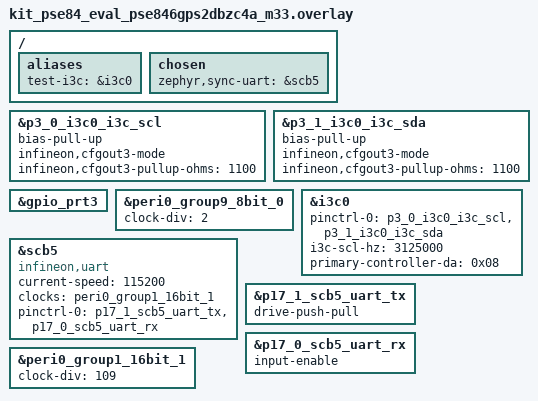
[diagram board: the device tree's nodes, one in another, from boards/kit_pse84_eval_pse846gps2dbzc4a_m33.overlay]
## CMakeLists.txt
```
# SPDX-FileCopyrightText: Copyright (c) 2026 Infineon Technologies AG,
# SPDX-FileCopyrightText: or an affiliate of Infineon Technologies AG. All rights reserved.
#
# SPDX-License-Identifier: Apache-2.0

cmake_minimum_required(VERSION 3.20.0)
find_package(Zephyr REQUIRED HINTS $ENV{ZEPHYR_BASE})
project(dual_board_loopback_controller)

file(GLOB app_sources CONFIGURE_DEPENDS src/*.c)
list(REMOVE_ITEM app_sources "${CMAKE_CURRENT_SOURCE_DIR}/src/test_harness.c")
target_sources(app PRIVATE ${app_sources})
target_sources_ifdef(CONFIG_I3C_DUAL_BOARD_LOOPBACK_META_TESTS app PRIVATE src/test_harness.c)

target_include_directories(app PRIVATE ${CMAKE_CURRENT_SOURCE_DIR}/../../common)
```

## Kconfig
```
# SPDX-FileCopyrightText: Copyright (c) 2026 Infineon Technologies AG,
# SPDX-FileCopyrightText: or an affiliate of Infineon Technologies AG. All rights reserved.
#
# SPDX-License-Identifier: Apache-2.0

mainmenu "I3C loopback test (controller)"

source "Kconfig.zephyr"

menu "I3C loopback bench options"

config I3C_DUAL_BOARD_LOOPBACK_META_TESTS
	bool "Build the meta tests that exercise the loopback fixture"
	help
	  Build the ``meta_*`` ZTESTs in test_harness.c.  These test the
	  fixture in main.c rather than the I3C driver: they deliberately
	  corrupt the target descriptor to prove the recovery path in
	  dual_board_loopback_heal_target() puts it back.  Because they run before
	  the driver tests and mutate shared bus state, a regression in the
	  fixture makes them cascade into every later test, so keep them off
	  for routine runs and enable them when changing the harness.

endmenu
```

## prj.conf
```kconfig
# SPDX-FileCopyrightText: Copyright (c) 2026 Infineon Technologies AG,
# SPDX-FileCopyrightText: or an affiliate of Infineon Technologies AG. All rights reserved.
#
# SPDX-License-Identifier: Apache-2.0
#
# Controller app for the dual_board_loopback two-board test pair.

CONFIG_ZTEST=y
CONFIG_ZTEST_STACK_SIZE=4096

CONFIG_PRINTK_SYNC=y
CONFIG_FAULT_DUMP=2
CONFIG_LOG=y
CONFIG_SERIAL=y

# I3C: controller-only build for max coverage of the controller paths
CONFIG_I3C=y
CONFIG_I3C_CONTROLLER_ROLE_ONLY=y
CONFIG_I3C_USE_IBI=y

# Misc
CONFIG_PINCTRL_KEEP_SLEEP_STATE=y
CONFIG_MAIN_STACK_SIZE=4096
CONFIG_CLOCK_CONTROL=y

# For light testing of PM APIs - this suite does not do extensive PM
# validaton
CONFIG_PM_DEVICE=y
```

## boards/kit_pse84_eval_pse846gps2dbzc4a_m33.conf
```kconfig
# SPDX-FileCopyrightText: Copyright (c) 2026 Infineon Technologies AG,
# SPDX-FileCopyrightText: or an affiliate of Infineon Technologies AG. All rights reserved.
#
# SPDX-License-Identifier: Apache-2.0
#
# Bench configuration for KIT_PSE84_EVAL (PSE846GPS2DBZC4A, M33 core).
#
# The SOM has a BMM350 magnetometer wired to the same I3C0 pads the test
# controller drives, with no power-enable or isolation jumper exposed.
# It only joins ENTDAA while it is in I3C mode: it falls back to its I2C
# interface whenever anything issues a soft reset to it, and only a power
# cycle puts it back.  Because the suite cannot rely on it being there
# from one run to the next, the placeholder descriptor is left disabled
# and the address it would take is treated as free.
#
# Re-enable these if the BMM350 is made to stay in I3C mode.  The PID was
# captured live from DEV_CHAR_TABLE on this SOM.
# CONFIG_I3C_DUAL_BOARD_LOOPBACK_BENCH_HAS_PERMANENT_TARGET=y
# CONFIG_I3C_DUAL_BOARD_LOOPBACK_BENCH_PERMANENT_TARGET_PID_HI=0x0770
# CONFIG_I3C_DUAL_BOARD_LOOPBACK_BENCH_PERMANENT_TARGET_PID_LO=0x10331000
# CONFIG_I3C_DUAL_BOARD_LOOPBACK_BENCH_PERMANENT_TARGET_INIT_DA=0x15
```

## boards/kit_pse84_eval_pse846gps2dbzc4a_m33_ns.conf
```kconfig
# SPDX-FileCopyrightText: Copyright (c) 2026 Infineon Technologies AG,
# SPDX-FileCopyrightText: or an affiliate of Infineon Technologies AG. All rights reserved.
#
# SPDX-License-Identifier: Apache-2.0
#
# Bench configuration for KIT_PSE84_EVAL (PSE846GPS2DBZC4A, M33 non-secure
# core, TF-M).
#
# The SOM has a BMM350 magnetometer wired to the same I3C0 pads the test
# controller drives, with no power-enable or isolation jumper exposed.
# It only joins ENTDAA while it is in I3C mode: it falls back to its I2C
# interface whenever anything issues a soft reset to it, and only a power
# cycle puts it back.  Because the suite cannot rely on it being there
# from one run to the next, the placeholder descriptor is left disabled
# and the address it would take is treated as free.
#
# Re-enable these if the BMM350 is made to stay in I3C mode.  The PID was
# captured live from DEV_CHAR_TABLE on this SOM.
# CONFIG_I3C_DUAL_BOARD_LOOPBACK_BENCH_HAS_PERMANENT_TARGET=y
# CONFIG_I3C_DUAL_BOARD_LOOPBACK_BENCH_PERMANENT_TARGET_PID_HI=0x0770
# CONFIG_I3C_DUAL_BOARD_LOOPBACK_BENCH_PERMANENT_TARGET_PID_LO=0x10331000
# CONFIG_I3C_DUAL_BOARD_LOOPBACK_BENCH_PERMANENT_TARGET_INIT_DA=0x15
```

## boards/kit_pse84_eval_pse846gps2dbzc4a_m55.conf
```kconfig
# SPDX-FileCopyrightText: Copyright (c) 2026 Infineon Technologies AG,
# SPDX-FileCopyrightText: or an affiliate of Infineon Technologies AG. All rights reserved.
#
# SPDX-License-Identifier: Apache-2.0
#
# Bench configuration for KIT_PSE84_EVAL (PSE846GPS2DBZC4A, M55 core).
#
# This core must be built with --sysbuild: the CM55 image only boots once
# the CM33 enable_cm55 companion has released it, and sysbuild is what
# generates that companion.  A command-line Kconfig override has to name
# the image as well, because a bare -DCONFIG_* lands in sysbuild's own
# namespace and never reaches the application:
#
#   west build -b kit_pse84_eval/pse846gps2dbzc4a/m55 --sysbuild \
#         tests/drivers/i3c/dual_board_loopback/controller_driven/i3c_controller \
#         -- -Di3c_controller_CONFIG_I3C_USE_IBI=n
#
# The SOM has a BMM350 magnetometer wired to the same I3C0 pads the test
# controller drives, with no power-enable or isolation jumper exposed.
# It only joins ENTDAA while it is in I3C mode: it falls back to its I2C
# interface whenever anything issues a soft reset to it, and only a power
# cycle puts it back.  Because the suite cannot rely on it being there
# from one run to the next, the placeholder descriptor is left disabled
# and the address it would take is treated as free.
#
# Re-enable these if the BMM350 is made to stay in I3C mode.  The PID was
# captured live from DEV_CHAR_TABLE on this SOM.
# CONFIG_I3C_DUAL_BOARD_LOOPBACK_BENCH_HAS_PERMANENT_TARGET=y
# CONFIG_I3C_DUAL_BOARD_LOOPBACK_BENCH_PERMANENT_TARGET_PID_HI=0x0770
# CONFIG_I3C_DUAL_BOARD_LOOPBACK_BENCH_PERMANENT_TARGET_PID_LO=0x10331000
# CONFIG_I3C_DUAL_BOARD_LOOPBACK_BENCH_PERMANENT_TARGET_INIT_DA=0x15
```

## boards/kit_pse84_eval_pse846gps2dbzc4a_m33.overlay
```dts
/*
 * SPDX-FileCopyrightText: Copyright (c) 2026 Infineon Technologies AG,
 * SPDX-FileCopyrightText: or an affiliate of Infineon Technologies AG. All rights reserved.
 *
 * SPDX-License-Identifier: Apache-2.0
 *
 * Board overlay for the dual_board_loopback CONTROLLER (Board A) on
 * KIT_PSE84_EVAL (M33 core).
 *
 * Topology — I3C bus between two boards:
 *
 *   A.I3C0_SCL  ── B.I3C0_SCL    (P3.0 / B.P3.0)
 *   A.I3C0_SDA  ── B.I3C0_SDA    (P3.1 / B.P3.1)
 *
 * UART sync channel (separate from the I3C bus):
 *
 *   A.SCB5_TX (P17.1)  ──── B.SCB5_RX (P17.0)
 *   A.SCB5_RX (P17.0)  ──── B.SCB5_TX (P17.1)
 *
 * SCB5 was selected after SCB1 (separate non-LPSS IP block at
 * 0x42d00000) refused to drain its TX FIFO regardless of clock /
 * pinctrl configuration.  SCB5 (LPSS, 0x429d0000) is the same UART
 * instance used by tests/drivers/uart/uart_async_api on this board
 * and was validated end-to-end by tests/drivers/serial/uart_sync_loopback.
 */

/ {
	aliases {
		test-i3c = &i3c0;
	};

	chosen {
		zephyr,sync-uart = &scb5;
	};
};

/*
 * Mandatory CFGOUT3 mode on the I3C SCL/SDA pads.  Without this the DW
 * I3C ACK detector cannot sample SDA and every transfer reports
 * ADDRESS_NACK (see tests/drivers/i3c/i3c_i2c/boards/<...>.overlay for
 * the full rationale).
 */
&p3_0_i3c0_i3c_scl {
	bias-pull-up;
	infineon,cfgout3-mode;
	infineon,cfgout3-pullup-ohms = <1100>;
};

&p3_1_i3c0_i3c_sda {
	bias-pull-up;
	infineon,cfgout3-mode;
	infineon,cfgout3-pullup-ohms = <1100>;
};

&gpio_prt3 {
	status = "okay";
};

/*
 * I3C protocol clock (CORE_CLK).
 *
 * CLK_HF[13] = CLKPATH0 / 4 = 400 MHz / 4 = 100 MHz.
 * peri0_group9_8bit_0 divides that further: 100 MHz / 2 = 50 MHz.
 *
 * The core clock must exceed 5 * i3c-scl-hz: the driver computes the
 * push-pull lcnt as DIV_ROUND_UP(core, scl) - hcnt with hcnt floored at
 * 5, so a slower core underflows and clamps lcnt to 255, collapsing SCL
 * to core/260 instead of the requested rate.  At 50 MHz, hcnt=5 lcnt=11
 * gives the requested 3.125 MHz.
 */
&peri0_group9_8bit_0 {
	clock-div = <2>;
	status = "okay";
};

&i3c0 {
	pinctrl-0 = <&p3_0_i3c0_i3c_scl &p3_1_i3c0_i3c_sda>;
	pinctrl-names = "default";
	i3c-scl-hz = <3125000>;
	primary-controller-da = <0x08>;
	status = "okay";

	/*
	 * Note: Board B is intentionally NOT declared as an i3c child
	 * node in DT.  Doing so would require a real driver matching the
	 * compatible (DEVICE_DT_GET would otherwise link-fail).  The
	 * controller-side test code instead populates a static
	 * `struct i3c_device_desc` programmatically and calls
	 * i3c_attach_i3c_device() at suite setup, which exercises the
	 * dynamic-attach path of the driver.
	 */
};

/*
 * SCB5 — UART sync channel between Board A and Board B.
 *   P17.1 SCB5_UART_TX, P17.0 SCB5_UART_RX
 * Pinctrl reused from the SoC pin database (omit-if-no-ref).
 * (See file header for SCB1 history.)
 */
scb5_sync_uart: &scb5 {
	compatible = "infineon,uart";
	current-speed = <115200>;
	clocks = <&peri0_group1_16bit_1>;
	pinctrl-0 = <&p17_1_scb5_uart_tx &p17_0_scb5_uart_rx>;
	pinctrl-names = "default";
	status = "okay";
};

&p17_1_scb5_uart_tx {
	drive-push-pull;
};

&p17_0_scb5_uart_rx {
	input-enable;
};

&peri0_group1_16bit_1 {
	clock-div = <109>;
	status = "okay";
};
```

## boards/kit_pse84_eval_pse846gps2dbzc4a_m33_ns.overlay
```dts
/*
 * SPDX-FileCopyrightText: Copyright (c) 2026 Infineon Technologies AG,
 * SPDX-FileCopyrightText: or an affiliate of Infineon Technologies AG. All rights reserved.
 *
 * SPDX-License-Identifier: Apache-2.0
 *
 * Board overlay for the dual_board_loopback CONTROLLER (Board A) on
 * KIT_PSE84_EVAL (M33 non-secure core, TF-M).
 *
 * Topology — I3C bus between two boards:
 *
 *   A.I3C0_SCL  ── B.I3C0_SCL    (P3.0 / B.P3.0)
 *   A.I3C0_SDA  ── B.I3C0_SDA    (P3.1 / B.P3.1)
 *
 * UART sync channel (separate from the I3C bus):
 *
 *   A.SCB5_TX (P17.1)  ──── B.SCB5_RX (P17.0)
 *   A.SCB5_RX (P17.0)  ──── B.SCB5_TX (P17.1)
 */

/ {
	aliases {
		test-i3c = &i3c0;
	};

	chosen {
		zephyr,sync-uart = &scb5;
	};
};

/*
 * Mandatory CFGOUT3 mode on the I3C SCL/SDA pads.  Without this the DW
 * I3C ACK detector cannot sample SDA and every transfer reports
 * ADDRESS_NACK (see tests/drivers/i3c/i3c_i2c/boards/<...>.overlay for
 * the full rationale).
 */
&p3_0_i3c0_i3c_scl {
	bias-pull-up;
	infineon,cfgout3-mode;
	infineon,cfgout3-pullup-ohms = <1100>;
};

&p3_1_i3c0_i3c_sda {
	bias-pull-up;
	infineon,cfgout3-mode;
	infineon,cfgout3-pullup-ohms = <1100>;
};

&gpio_prt3 {
	status = "okay";
};

/*
 * I3C protocol clock (CORE_CLK).
 *
 * CLK_HF[13] = CLKPATH0 / 4 = 400 MHz / 4 = 100 MHz.
 * peri0_group9_8bit_0 divides that further: 100 MHz / 2 = 50 MHz.
 *
 * The core clock must exceed 5 * i3c-scl-hz: the driver computes the
 * push-pull lcnt as DIV_ROUND_UP(core, scl) - hcnt with hcnt floored at
 * 5, so a slower core underflows and clamps lcnt to 255, collapsing SCL
 * to core/260 instead of the requested rate.  At 50 MHz, hcnt=5 lcnt=11
 * gives the requested 3.125 MHz.
 */
&peri0_group9_8bit_0 {
	clock-div = <2>;
	status = "okay";
};

&i3c0 {
	pinctrl-0 = <&p3_0_i3c0_i3c_scl &p3_1_i3c0_i3c_sda>;
	pinctrl-names = "default";
	i3c-scl-hz = <3125000>;
	primary-controller-da = <0x08>;
	status = "okay";

	/*
	 * Note: Board B is intentionally NOT declared as an i3c child
	 * node in DT.  Doing so would require a real driver matching the
	 * compatible (DEVICE_DT_GET would otherwise link-fail).  The
	 * controller-side test code instead populates a static
	 * `struct i3c_device_desc` programmatically and calls
	 * i3c_attach_i3c_device() at suite setup, which exercises the
	 * dynamic-attach path of the driver.
	 */
};

/*
 * SCB5 — UART sync channel between Board A and Board B.
 *   P17.1 SCB5_UART_TX, P17.0 SCB5_UART_RX
 * Pinctrl reused from the SoC pin database (omit-if-no-ref).
 */
scb5_sync_uart: &scb5 {
	compatible = "infineon,uart";
	current-speed = <115200>;
	clocks = <&peri0_group1_16bit_1>;
	pinctrl-0 = <&p17_1_scb5_uart_tx &p17_0_scb5_uart_rx>;
	pinctrl-names = "default";
	status = "okay";
};

&p17_1_scb5_uart_tx {
	drive-push-pull;
};

&p17_0_scb5_uart_rx {
	input-enable;
};

&peri0_group1_16bit_1 {
	clock-div = <109>;
	status = "okay";
};
```

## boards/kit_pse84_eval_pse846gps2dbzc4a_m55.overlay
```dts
/*
 * SPDX-FileCopyrightText: Copyright (c) 2026 Infineon Technologies AG,
 * SPDX-FileCopyrightText: or an affiliate of Infineon Technologies AG. All rights reserved.
 *
 * SPDX-License-Identifier: Apache-2.0
 *
 * Board overlay for the dual_board_loopback CONTROLLER (Board A) on
 * KIT_PSE84_EVAL (M55 core).
 *
 * Topology — I3C bus between two boards:
 *
 *   A.I3C0_SCL  ── B.I3C0_SCL    (P3.0 / B.P3.0)
 *   A.I3C0_SDA  ── B.I3C0_SDA    (P3.1 / B.P3.1)
 *
 * UART sync channel (separate from the I3C bus):
 *
 *   A.SCB5_TX (P17.1)  ──── B.SCB5_RX (P17.0)
 *   A.SCB5_RX (P17.0)  ──── B.SCB5_TX (P17.1)
 *
 * SCB5 was selected after SCB1 (separate non-LPSS IP block at
 * 0x42d00000) refused to drain its TX FIFO regardless of clock /
 * pinctrl configuration.  SCB5 (LPSS, 0x429d0000) is the same UART
 * instance used by tests/drivers/uart/uart_async_api on this board
 * and was validated end-to-end by tests/drivers/serial/uart_sync_loopback.
 */

/ {
	aliases {
		test-i3c = &i3c0;
	};

	chosen {
		zephyr,sync-uart = &scb5;
	};
};

/*
 * Mandatory CFGOUT3 mode on the I3C SCL/SDA pads.  Without this the DW
 * I3C ACK detector cannot sample SDA and every transfer reports
 * ADDRESS_NACK (see tests/drivers/i3c/i3c_i2c/boards/<...>.overlay for
 * the full rationale).
 */
&p3_0_i3c0_i3c_scl {
	bias-pull-up;
	infineon,cfgout3-mode;
	infineon,cfgout3-pullup-ohms = <1100>;
};

&p3_1_i3c0_i3c_sda {
	bias-pull-up;
	infineon,cfgout3-mode;
	infineon,cfgout3-pullup-ohms = <1100>;
};

&gpio_prt3 {
	status = "okay";
};

/*
 * I3C protocol clock (CORE_CLK).
 *
 * CLK_HF[13] = CLKPATH0 / 4 = 400 MHz / 4 = 100 MHz.
 * peri0_group9_8bit_0 divides that further: 100 MHz / 2 = 50 MHz.
 *
 * The core clock must exceed 5 * i3c-scl-hz: the driver computes the
 * push-pull lcnt as DIV_ROUND_UP(core, scl) - hcnt with hcnt floored at
 * 5, so a slower core underflows and clamps lcnt to 255, collapsing SCL
 * to core/260 instead of the requested rate.  At 50 MHz, hcnt=5 lcnt=11
 * gives the requested 3.125 MHz.
 */
&peri0_group9_8bit_0 {
	clock-div = <2>;
	status = "okay";
};

&i3c0 {
	pinctrl-0 = <&p3_0_i3c0_i3c_scl &p3_1_i3c0_i3c_sda>;
	pinctrl-names = "default";
	i3c-scl-hz = <3125000>;
	primary-controller-da = <0x08>;
	status = "okay";

	/*
	 * Note: Board B is intentionally NOT declared as an i3c child
	 * node in DT.  Doing so would require a real driver matching the
	 * compatible (DEVICE_DT_GET would otherwise link-fail).  The
	 * controller-side test code instead populates a static
	 * `struct i3c_device_desc` programmatically and calls
	 * i3c_attach_i3c_device() at suite setup, which exercises the
	 * dynamic-attach path of the driver.
	 */
};

/*
 * SCB5 — UART sync channel between Board A and Board B.
 *   P17.1 SCB5_UART_TX, P17.0 SCB5_UART_RX
 * Pinctrl reused from the SoC pin database (omit-if-no-ref).
 * (See file header for SCB1 history.)
 */
scb5_sync_uart: &scb5 {
	compatible = "infineon,uart";
	current-speed = <115200>;
	clocks = <&peri0_group1_16bit_1>;
	pinctrl-0 = <&p17_1_scb5_uart_tx &p17_0_scb5_uart_rx>;
	pinctrl-names = "default";
	status = "okay";
};

&p17_1_scb5_uart_tx {
	drive-push-pull;
};

&p17_0_scb5_uart_rx {
	input-enable;
};

&peri0_group1_16bit_1 {
	clock-div = <109>;
	status = "okay";
};
```

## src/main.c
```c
/*
 * SPDX-FileCopyrightText: Copyright (c) 2026 Infineon Technologies AG,
 * SPDX-FileCopyrightText: or an affiliate of Infineon Technologies AG. All rights reserved.
 *
 * SPDX-License-Identifier: Apache-2.0
 *
 * Controller-side fixture for the dual_board_loopback two-board test pair.
 * Owns DT handles, the Board B target descriptor (attached at suite
 * setup), and the ZTEST_SUITE registration.  Per-test ZTEST() bodies
 * live in the other src/test_*.c files.
 */

#include "test_common.h"
#include "test_identity.h"

#include <zephyr/devicetree.h>
#include <zephyr/sys/sys_io.h>
#include <zephyr/drivers/i3c.h>
#include <zephyr/drivers/i3c/ccc.h>
#include <zephyr/drivers/uart.h>
#include <zephyr/kernel.h>
#include <zephyr/logging/log.h>
#include <zephyr/ztest.h>
#include <zephyr/init.h>
#include <string.h>

LOG_MODULE_REGISTER(dual_board_loopback_ctrl, LOG_LEVEL_INF);

/* Early boot marker to prove flash is working */
static int early_boot_marker(void)
{
	printk("\n\n*** CONTROLLER BUILD " __DATE__ " " __TIME__ " ***\n\n");
	return 0;
}
SYS_INIT(early_boot_marker, APPLICATION, 0);

/*
 * --------------------------------------------------------------------------
 * DT handles
 * --------------------------------------------------------------------------
 */
const struct device *const i3c_dev = DEVICE_DT_GET(DT_ALIAS(test_i3c));
const struct device *const sync_uart = DEVICE_DT_GET(DT_CHOSEN(zephyr_sync_uart));

/*
 * Stand-in driver instance for every peer descriptor this suite builds by
 * hand; see the comment on the declaration in test_common.h.
 */
const struct device i3c_peer_dev = {
	.name = "i3c-peer",
};

/*
 * Board B (I3C target) descriptor.  Both endpoints are known at build
 * time, so Board B is enumerated via SETDASA from its known static
 * address; PID is still carried so directed CCCs can verify identity.
 */
struct i3c_device_desc target_b_desc = {
	.bus = DEVICE_DT_GET(DT_ALIAS(test_i3c)),
	.dev = &i3c_peer_dev,
	.pid = TARGET_PID,
	.static_addr = TARGET_STATIC_ADDR,
	.init_dynamic_addr = TARGET_STATIC_ADDR,
	.flags = 0,
};

int dual_board_loopback_heal_target(void)
{
	struct i3c_ccc_address da = {.addr = CCC_ADDR_PAYLOAD(TARGET_STATIC_ADDR)};
	uint8_t prev_da = target_b_desc.dynamic_addr;
	int rc;

	if (prev_da == 0U) {
		prev_da = TARGET_STATIC_ADDR;
	}

	sync_send(sync_uart, "SOFT_RST");
	(void)sync_expect(sync_uart, "READY", K_MSEC(2000));
	(void)i3c_recover_bus(i3c_dev);
	k_msleep(200);
	(void)i3c_ccc_do_rstdaa_all(i3c_dev);

	/*
	 * SETDASA is only legal for a device with no dynamic address, and the
	 * driver keys the DAT entry on whatever address the descriptor holds
	 * at attach time. Detach, clear, re-attach so the CCC and the table
	 * agree the target is currently unaddressed. Detach frees the address
	 * slot named by the descriptor, so point it at the reserved address
	 * first; a stale DA would free the wrong slot and leak the real one.
	 */
	target_b_desc.dynamic_addr = TARGET_STATIC_ADDR;
	(void)i3c_detach_i3c_device(&target_b_desc);
	target_b_desc.dynamic_addr = 0U;

	rc = i3c_attach_i3c_device(&target_b_desc);
	if ((rc != 0) && (rc != -EALREADY)) {
		printk("[heal] re-attach failed (%d)\n", rc);
		target_b_desc.dynamic_addr = prev_da;
		return rc;
	}

	/* SETDASA (not ENTDAA) restores the known static address; ENTDAA
	 * could yield a different DA after arbitration against another
	 * on-bus target.
	 */
	rc = i3c_ccc_do_setdasa(&target_b_desc, da);
	if (rc != 0) {
		/* Restore prev_da so the next before_each retries instead of
		 * treating the target as permanently absent.
		 */
		target_b_desc.dynamic_addr = prev_da;
		return rc;
	}

	/*
	 * Re-attach rather than reattach: the driver only writes the DAT
	 * dynamic-address field when dynamic_addr is already set, and
	 * i3c_reattach_i3c_device() bails with -EADDRNOTAVAIL here because
	 * the attach above already claimed this address slot.
	 */
	(void)i3c_detach_i3c_device(&target_b_desc);
	target_b_desc.dynamic_addr = TARGET_STATIC_ADDR;
	rc = i3c_attach_i3c_device(&target_b_desc);
	if (rc == -EALREADY) {
		rc = 0;
	}

	return rc;
}

/* Suite setup: ready DT devices, handshake with Board B, attach and
 * enumerate it.
 */
static void *suite_setup(void)
{
	int rc;
	uint32_t t0, t1;

	printk(">>> SUITE_SETUP ENTER\n");

	t0 = (uint32_t)k_uptime_get();
	printk("[t=%u] device_is_ready checks\n", t0);
	zassert_true(device_is_ready(i3c_dev), "I3C controller %s not ready", i3c_dev->name);
	zassert_true(device_is_ready(sync_uart), "Sync UART %s not ready", sync_uart->name);

	/*
	 * Three-way HELLO with Board B over the sync UART; if it fails,
	 * skip i3c_bus_init() and let bus-traffic tests FAIL via
	 * I3C_DUAL_BOARD_LOOPBACK_REQUIRE_TARGET_DA() rather than crash the suite
	 * on the DW driver's NULL-deref CCC abort path.
	 */
	t1 = (uint32_t)k_uptime_get();
	printk("[t=%u] sync_handshake start\n", t1);
	/* Drain RX junk accumulated while Board B was being flashed. */
	sync_drain(sync_uart);
	{
		const k_timepoint_t deadline = sys_timepoint_calc(K_SECONDS(60));

		rc = -EAGAIN;
		while (!sys_timepoint_expired(deadline)) {
			char boot_line[SYNC_LINE_MAX];

			/*
			 * Board B announces BOOT until it is spoken to, so
			 * waiting for an announcement rather than assuming a
			 * listening peer is what makes the flashing order
			 * irrelevant: a Board B that is already running stopped
			 * announcing long ago, and a stale image answers HELLO
			 * just as readily as a freshly programmed one.
			 */
			if (sync_expect_line(sync_uart, "BOOT", boot_line, sizeof(boot_line),
					     sys_timepoint_timeout(deadline)) != 0) {
				break;
			}
			/* Answering stops the announcements. */
			if (sync_handshake(sync_uart, K_SECONDS(5)) != 0) {
				continue;
			}
			/* Programming Board B resets it twice on sysbuild
			 * targets, so a further announcement means the peer we
			 * just greeted is already gone.
			 */
			if (sync_expect_line(sync_uart, "BOOT", boot_line, sizeof(boot_line),
					     K_SECONDS(2)) != 0) {
				rc = 0;
				break;
			}
		}
	}
	t1 = (uint32_t)k_uptime_get();
	printk("[t=%u] sync_handshake => %d\n", t1, rc);
	if (rc != 0) {
		printk("*** TARGET ABSENT (sync_handshake rc=%d) — "
		       "skipping i3c_bus_init; bus-traffic tests will FAIL "
		       "via I3C_DUAL_BOARD_LOOPBACK_REQUIRE_TARGET_DA ***\n",
		       rc);
		return NULL;
	}

	/*
	 * Attach target_b BEFORE bus init so the driver's PID lookup
	 * matches it during ENTDAA and fills in dynamic_addr / bcr / dcr
	 * directly on our descriptor.
	 */
	t1 = (uint32_t)k_uptime_get();
	printk("[t=%u] attach target_b (PID 0x%04x%08x)\n", t1, (uint16_t)(TARGET_PID >> 32),
	       (uint32_t)(TARGET_PID & 0xFFFFFFFFU));
	rc = i3c_attach_i3c_device(&target_b_desc);
	zassert_ok(rc, "i3c_attach_i3c_device(target_b) failed (%d)", rc);

	t1 = (uint32_t)k_uptime_get();
	printk("[t=%u] calling i3c_bus_init\n", t1);
	{
		struct i3c_dev_list dev_list = {
			.i3c = &target_b_desc,
			.i2c = NULL,
			.num_i3c = 1,
			.num_i2c = 0,
		};

		rc = i3c_bus_init(i3c_dev, &dev_list);
	}
	t1 = (uint32_t)k_uptime_get();
	printk("[t=%u] i3c_bus_init => %d\n", t1, rc);
	printk("[t=%u] target_b dynamic_addr = 0x%02x  bcr=0x%02x  dcr=0x%02x\n",
	       (uint32_t)k_uptime_get(), target_b_desc.dynamic_addr, target_b_desc.bcr,
	       target_b_desc.dcr);

	if (target_b_desc.dynamic_addr == 0) {
		int hrc = dual_board_loopback_heal_target();

		printk("[setup] bus init left no DA; heal rc=%d DA=0x%02x\n", hrc,
		       target_b_desc.dynamic_addr);
	}

	if (target_b_desc.dynamic_addr == 0) {
		printk("*** TARGET NOT FOUND ON BUS — tests will skip ***\n");
	}

	/*
	 * The bench-permanent target descriptor (if any) stays attached
	 * for the whole suite: mid-suite RSTDAA broadcasts force every
	 * on-bus target to re-arbitrate, and without a bound descriptor
	 * the driver hands the next-free DA to the unknown PID and can
	 * end up stealing target_b's slot.
	 */

	return NULL;
}

static void suite_before_each(void *fixture)
{
	ARG_UNUSED(fixture);

	sync_drain(sync_uart);
	sync_send(sync_uart, "RESET");
	{
		char ready_line[128];
		int rc = sync_expect_line(sync_uart, "READY", ready_line, sizeof(ready_line),
					  K_MSEC(100));
		if (rc == 0) {
			LOG_INF("[before_each] %s", ready_line);
		}
	}

	/* If a previous test left target_b without a DA, recover via
	 * ENTDAA.  The bench-permanent descriptor (if any) remains
	 * attached so it doesn't steal target_b's slot.
	 */
	if (target_b_desc.dynamic_addr == 0U) {
		int rc = i3c_do_daa(i3c_dev);

		if (rc != 0) {
			printk("[before_each] ENTDAA recovery failed: %d\n", rc);
		}

		/* ENTDAA cannot match a descriptor the driver has detached,
		 * so fall back to re-attach + SETDASA.
		 */
		if (target_b_desc.dynamic_addr == 0U) {
			rc = dual_board_loopback_heal_target();
			printk("[before_each] SETDASA heal rc=%d DA=0x%02x\n", rc,
			       target_b_desc.dynamic_addr);
		}
	}

	/* Recover from any HALT state left by a previous test. */
	(void)i3c_recover_bus(i3c_dev);

	/* Probe target with a 1-byte write; retry on NACK (legitimate
	 * I3C flow control while the target clears SLAVE_BUSY).  Only
	 * re-enumerate if all retries fail.
	 */
	if (target_b_desc.dynamic_addr != 0U) {
		uint8_t probe = 0x00;
		struct i3c_msg msg = {
			.buf = &probe,
			.len = 1,
			.flags = I3C_MSG_WRITE | I3C_MSG_STOP,
		};
		int rc = -1;

		/* Probe the target: 20 × 10 ms (~200 ms total).  Memory
		 * notes: the target IP recovers from its post-large-W NACK
		 * state within ~100-200 ms.  k_msleep yields so kernel
		 * timers/IRQs can run.
		 */
		for (int attempt = 0; attempt < 20; attempt++) {
			rc = i3c_transfer(&target_b_desc, &msg, 1);
			if (rc == 0) {
				break;
			}
			k_msleep(10);
		}

		if (rc != 0) {
			printk("[before_each] probe failed (%d) after retries, "
			       "re-enumerating\n",
			       rc);

			rc = dual_board_loopback_heal_target();
			printk("[before_each] re-enum done, DA=0x%02x "
			       "rc=%d\n",
			       target_b_desc.dynamic_addr, rc);

			/* Post re-enum settle + verify, same 200 ms budget. */
			k_msleep(50);
			for (int attempt = 0; attempt < 20; attempt++) {
				rc = i3c_transfer(&target_b_desc, &msg, 1);
				if (rc == 0) {
					break;
				}
				k_msleep(10);
			}
			if (rc != 0) {
				printk("[before_each] post-renum probe still "
				       "failing (%d), keeping DA so subsequent "
				       "tests can retry recovery (this test "
				       "will fail rather than skip)\n",
				       rc);
				/*
				 * Do NOT clear target_b_desc.dynamic_addr.
				 * The target typically recovers within 100-200
				 * ms, so the next before_each's probe usually
				 * succeeds.  Clearing the DA marks the target
				 * dead and would skip the rest of the suite.
				 * Better policy: this test FAILs honestly,
				 * the next test gets a fresh recovery attempt.
				 */
			}
		}

		/* Clear sticky OVERFLOW/UNDERFLOW/PROTOCOL_ERR via directed
		 * GETSTATUS (databook §3.5.2 / §6.1.24: the controller NACKs
		 * further private xfers until GETSTATUS reads device status).
		 * If GETSTATUS itself NACKs, the IP halts — recover so the
		 * halt does not cascade.
		 */
		if (target_b_desc.dynamic_addr != 0U) {
			union i3c_ccc_getstatus gs;
			int gs_rc = i3c_ccc_do_getstatus_fmt1(&target_b_desc, &gs);

			if (gs_rc != 0) {
				LOG_WRN("[before_each] GETSTATUS failed: %d", gs_rc);
			} else if (gs.fmt1.status != 0U) {
				LOG_INF("[before_each] GETSTATUS=0x%04x", gs.fmt1.status);
			}
		}
	}
}

static void suite_after_each(void *fixture)
{
	ARG_UNUSED(fixture);

	dual_board_loopback_attach_cleanup();
}

static void suite_teardown(void *data)
{
	ARG_UNUSED(data);

	(void)i3c_detach_i3c_device(&target_b_desc);
}

ZTEST_SUITE(dual_board_loopback, NULL, suite_setup, suite_before_each, suite_after_each,
	    suite_teardown);
```

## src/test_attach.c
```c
/*
 * SPDX-FileCopyrightText: Copyright (c) 2026 Infineon Technologies AG,
 * SPDX-FileCopyrightText: or an affiliate of Infineon Technologies AG. All rights reserved.
 *
 * SPDX-License-Identifier: Apache-2.0
 *
 * Group 4: Attach / detach / reattach.  Exercises
 *   dw_i3c_attach_device, dw_i3c_detach_device, dw_i3c_reattach_device,
 *   i3c_addr_slots tracking.
 */

#include "test_common.h"
#include "test_identity.h"
#include <string.h>

#include <zephyr/drivers/i3c/ccc.h>

/*
 * i3c_attach_i3c_device() appends &desc->node to a driver-owned list, so
 * the driver keeps this pointer until detach.  A failing zassert aborts
 * the test before its detach runs, so these must not live on the stack.
 */
#define TEST_ATTACH_SCRATCH_DESCS 4

/*
 * Scratch PIDs never reach the bus - attach does not inspect the field and
 * these descriptors are never addressed.  They exist only to identify a
 * descriptor in a memory dump, so the sole requirement is that each value
 * differs from the others and from TARGET_PID.
 */
#define SCRATCH_PID_VENDOR 0xF0CACC1A
#define SCRATCH_PID(part)  ((((uint64_t)SCRATCH_PID_VENDOR) << 32) | (uint32_t)(part))

/* One part number per test, so a stray descriptor names its origin. */
#define SCRATCH_PART_NO_ADDRESS       0x0001U
#define SCRATCH_PART_ALREADY_ATTACHED 0x0002U
#define SCRATCH_PART_RESERVES_ADDR    0x0003U
#define SCRATCH_PART_REATTACH_TAKEN   0x0004U
#define SCRATCH_PART_DUPLICATE_ADDR   0x0005U
#define SCRATCH_PART_NOT_ATTACHED     0x0006U
#define SCRATCH_PART_MULTI_FIRST      0x0010U

/* Judged by whether the transfer completes, not by what the target got. */
#define TEST_XFER_BYTE 0x5aU

static struct i3c_device_desc scratch_desc[TEST_ATTACH_SCRATCH_DESCS];
static bool scratch_attached[TEST_ATTACH_SCRATCH_DESCS];

static int scratch_attach_at(int i, uint64_t pid, uint8_t static_addr)
{
	int rc;

	/* struct i3c_device_desc has const members, so no struct assignment. */
	memset(&scratch_desc[i], 0, sizeof(scratch_desc[i]));
	scratch_desc[i].bus = i3c_dev;
	scratch_desc[i].pid = pid;
	scratch_desc[i].static_addr = static_addr;

	rc = i3c_attach_i3c_device(&scratch_desc[i]);
	if (rc == 0) {
		scratch_attached[i] = true;
	}

	return rc;
}

static int scratch_attach(int i, uint64_t pid)
{
	return scratch_attach_at(i, pid, 0U);
}

static int scratch_detach(int i)
{
	int rc;

	if (!scratch_attached[i]) {
		return 0;
	}

	rc = i3c_detach_i3c_device(&scratch_desc[i]);
	scratch_attached[i] = false;

	return rc;
}

void dual_board_loopback_attach_cleanup(void)
{
	for (int i = 0; i < TEST_ATTACH_SCRATCH_DESCS; i++) {
		int rc = scratch_detach(i);

		/* Reached only after a test already failed, so report
		 * rather than assert and mask the original failure.
		 */
		if (rc != 0) {
			printk("attach cleanup: detach %d returned %d\n", i, rc);
		}
	}
}

static bool scratch_on_bus_list(int i)
{
	return i3c_is_i3c_device_attached(&scratch_desc[i]);
}

ZTEST(dual_board_loopback, test_attach_device_without_address)
{
	int rc;

	rc = scratch_attach(0, SCRATCH_PID(SCRATCH_PART_NO_ADDRESS));
	zassert_ok(rc, "attach returned %d", rc);
	zassert_true(scratch_on_bus_list(0), "descriptor missing from attached list");

	/* dw_i3c_attach_device() stores the allocated DAT slot here. */
	zassert_not_null(scratch_desc[0].controller_priv, "attach allocated no DAT slot");

	rc = scratch_detach(0);
	zassert_ok(rc, "detach returned %d", rc);
	zassert_false(scratch_on_bus_list(0), "descriptor still on attached list after detach");
	zassert_is_null(scratch_desc[0].controller_priv, "detach released no DAT slot");
}

ZTEST(dual_board_loopback, test_detach_rejects_xfer)
{
	uint8_t buf = TEST_XFER_BYTE;
	struct i3c_msg msg = {
		.buf = &buf,
		.len = 1,
		.flags = I3C_MSG_WRITE | I3C_MSG_STOP,
	};
	int xfer_rc;
	int rc;

	I3C_DUAL_BOARD_LOOPBACK_REQUIRE_TARGET_DA();

	rc = i3c_detach_i3c_device(&target_b_desc);
	zassert_ok(rc, "detach returned %d", rc);

	xfer_rc = i3c_transfer(&target_b_desc, &msg, 1);

	/* Re-attach before asserting so a wrong xfer_rc cannot leave the
	 * shared target detached for every later test.
	 */
	rc = i3c_attach_i3c_device(&target_b_desc);
	zassert_ok(rc, "re-attach returned %d", rc);

	/* i3c_transfer() documents only 0/-EBUSY/-EIO and drivers disagree on
	 * which error a detached descriptor yields, so require only that it
	 * does not report success.
	 */
	zassert_not_equal(xfer_rc, 0, "transfer to a detached device reported success");
}

/*
 * Sibling of test_detach_rejects_xfer.  Detach removes the descriptor from the
 * driver's list; RSTDAA leaves it attached, holding its DAT slot, with no
 * dynamic address.  A private I3C transfer has no address to send in that
 * state, so it must not report success.
 */
ZTEST(dual_board_loopback, test_no_dynamic_addr_rejects_xfer)
{
	uint8_t buf = TEST_XFER_BYTE;
	struct i3c_msg msg = {
		.buf = &buf,
		.len = 1,
		.flags = I3C_MSG_WRITE | I3C_MSG_STOP,
	};
	struct i3c_ccc_address da = {.addr = CCC_ADDR_PAYLOAD(TARGET_STATIC_ADDR)};
	uint8_t da_after_rstdaa = 0xFFU;
	int xfer_rc = 0;
	int setdasa_rc;
	int reattach_rc = -1;
	int rc;

	I3C_DUAL_BOARD_LOOPBACK_REQUIRE_TARGET_DA();

	rc = i3c_ccc_do_rstdaa_all(i3c_dev);
	if (rc == 0) {
		da_after_rstdaa = target_b_desc.dynamic_addr;
		xfer_rc = i3c_transfer(&target_b_desc, &msg, 1);
	}

	/* Re-enumerate before asserting: a failing zassert aborts the test, and
	 * leaving target_b without a DA cascades into every later test.
	 */
	target_b_desc.dynamic_addr = 0;
	setdasa_rc = i3c_ccc_do_setdasa(&target_b_desc, da);
	if (setdasa_rc == 0) {
		/* Post-RSTDAA cleanup freed the address slot and a CCC cannot
		 * reserve it again; only re-attaching does.
		 */
		(void)i3c_detach_i3c_device(&target_b_desc);
		target_b_desc.dynamic_addr = TARGET_STATIC_ADDR;
		reattach_rc = i3c_attach_i3c_device(&target_b_desc);
	}

	printk("[nodaxfer] rstdaa=%d da_after=0x%02x xfer_rc=%d setdasa=%d reattach=%d\n", rc,
	       da_after_rstdaa, xfer_rc, setdasa_rc, reattach_rc);

	zassert_ok(rc, "RSTDAA all returned %d", rc);
	zassert_ok(setdasa_rc, "SETDASA re-enumeration after RSTDAA failed (%d)", setdasa_rc);
	zassert_ok(reattach_rc, "re-attach after SETDASA returned %d", reattach_rc);
	zassert_equal(da_after_rstdaa, 0U,
		      "precondition: RSTDAA left the descriptor holding DA 0x%02x",
		      da_after_rstdaa);
	zassert_not_equal(xfer_rc, 0,
			  "transfer to an attached target with no dynamic address "
			  "reported success");
}

ZTEST(dual_board_loopback, test_attach_already_attached)
{
	int rc;

	rc = scratch_attach(0, SCRATCH_PID(SCRATCH_PART_ALREADY_ATTACHED));
	zassert_ok(rc, "first attach returned %d", rc);

	/* Not scratch_attach(), which would clear the descriptor first. */
	rc = i3c_attach_i3c_device(&scratch_desc[0]);
	zassert_equal(rc, -EALREADY, "expected -EALREADY re-attaching, got %d", rc);

	zassert_true(scratch_on_bus_list(0), "rejected re-attach disturbed the attached list");

	rc = scratch_detach(0);
	zassert_ok(rc, "detach returned %d", rc);
}

ZTEST(dual_board_loopback, test_attach_reserves_address)
{
	struct i3c_driver_data *data = (struct i3c_driver_data *)i3c_dev->data;
	uint8_t addr_slot;
	int rc;

	addr_slot = i3c_addr_slots_next_free_find(&data->attached_dev.addr_slots, 0U);
	zassert_not_equal(addr_slot, 0U, "no free address available to attach at");

	rc = scratch_attach_at(0, SCRATCH_PID(SCRATCH_PART_RESERVES_ADDR), addr_slot);
	zassert_ok(rc, "attach at 0x%02x returned %d", addr_slot, rc);

	/* i3c.h states attach exists to reserve the address. */
	zassert_false(i3c_addr_slots_is_free(&data->attached_dev.addr_slots, addr_slot),
		      "address 0x%02x still free after attach", addr_slot);

	rc = scratch_detach(0);
	zassert_ok(rc, "detach returned %d", rc);
	zassert_true(i3c_addr_slots_is_free(&data->attached_dev.addr_slots, addr_slot),
		     "address 0x%02x not released by detach", addr_slot);
}

ZTEST(dual_board_loopback, test_reattach_rejects_taken_addr)
{
	int rc;

	I3C_DUAL_BOARD_LOOPBACK_REQUIRE_TARGET_DA();

	rc = scratch_attach(0, SCRATCH_PID(SCRATCH_PART_REATTACH_TAKEN));
	zassert_ok(rc, "attach returned %d", rc);

	scratch_desc[0].dynamic_addr = target_b_desc.dynamic_addr;
	rc = i3c_reattach_i3c_device(&scratch_desc[0], 0U);
	scratch_desc[0].dynamic_addr = 0U;

	/* i3c.h documents -EINVAL for this case; the implementation returns
	 * -EADDRNOTAVAIL, matching i3c_attach_i3c_device().
	 */
	zassert_equal(rc, -EADDRNOTAVAIL, "expected -EADDRNOTAVAIL reattaching onto 0x%02x, got %d",
		      target_b_desc.dynamic_addr, rc);

	rc = scratch_detach(0);
	zassert_ok(rc, "detach returned %d", rc);
}

ZTEST(dual_board_loopback, test_reattach_with_new_da)
{
	struct i3c_driver_data *data = (struct i3c_driver_data *)i3c_dev->data;
	uint8_t old_da = target_b_desc.dynamic_addr;
	uint8_t buf = TEST_XFER_BYTE;
	struct i3c_msg msg = {
		.buf = &buf,
		.len = 1,
		.flags = I3C_MSG_WRITE | I3C_MSG_STOP,
	};
	uint8_t new_da;
	int setnewda_rc;
	int reattach_rc = -1;
	int xfer_rc = -1;
	int restore_rc = 0;
	bool new_da_taken = false;
	bool old_da_freed = false;
	bool healed = false;

	I3C_DUAL_BOARD_LOOPBACK_REQUIRE_TARGET_DA();

	new_da = i3c_addr_slots_next_free_find(&data->attached_dev.addr_slots,
					       (uint8_t)(old_da + 1U));
	zassert_not_equal(new_da, 0U, "no free DA available for reattach");

	/* SETNEWDA is addressed to old_da, so it has to precede the reattach. */
	struct i3c_ccc_address to_new = {.addr = CCC_ADDR_PAYLOAD(new_da)};

	setnewda_rc = i3c_ccc_do_setnewda(&target_b_desc, to_new);

	if (setnewda_rc == 0) {
		target_b_desc.dynamic_addr = new_da;
		reattach_rc = i3c_reattach_i3c_device(&target_b_desc, old_da);

		new_da_taken = !i3c_addr_slots_is_free(&data->attached_dev.addr_slots, new_da);
		old_da_freed = i3c_addr_slots_is_free(&data->attached_dev.addr_slots, old_da);

		/* Reaches the target only if the reattach rewrote the DAT. */
		xfer_rc = i3c_transfer(&target_b_desc, &msg, 1);

		struct i3c_ccc_address to_old = {.addr = CCC_ADDR_PAYLOAD(old_da)};

		restore_rc = i3c_ccc_do_setnewda(&target_b_desc, to_old);
		if (restore_rc == 0) {
			target_b_desc.dynamic_addr = old_da;
			restore_rc = i3c_reattach_i3c_device(&target_b_desc, new_da);
		}
	}

	if (setnewda_rc != 0 || restore_rc != 0) {
		healed = (dual_board_loopback_heal_target() == 0);
	}

	/* All asserts at the end of the test to avoid a clean-up nightmare */
	zassert_ok(setnewda_rc, "SETNEWDA to 0x%02x returned %d", new_da, setnewda_rc);
	zassert_ok(reattach_rc, "reattach old=0x%02x new=0x%02x returned %d", old_da, new_da,
		   reattach_rc);
	zassert_true(new_da_taken, "new DA 0x%02x still free after reattach", new_da);
	zassert_true(old_da_freed, "old DA 0x%02x not freed by reattach", old_da);
	zassert_ok(xfer_rc, "transfer at reattached DA 0x%02x returned %d", new_da, xfer_rc);
	zassert_ok(restore_rc, "restore to DA 0x%02x returned %d (healed=%d)", old_da, restore_rc,
		   healed);
}

ZTEST(dual_board_loopback, test_attach_multiple_descriptors)
{
	void *slot[TEST_ATTACH_SCRATCH_DESCS] = {NULL};
	int detach_rc[TEST_ATTACH_SCRATCH_DESCS] = {0};
	bool all_listed = true;
	bool slots_distinct = true;
	int attached = 0;
	int rc = 0;

	for (int i = 0; i < TEST_ATTACH_SCRATCH_DESCS; i++) {
		rc = scratch_attach(i, SCRATCH_PID(SCRATCH_PART_MULTI_FIRST + i));
		if (rc != 0) {
			break;
		}
		slot[i] = scratch_desc[i].controller_priv;
		attached++;
	}

	/* Sampled while all descriptors are still attached. */
	for (int i = 0; i < attached; i++) {
		if (!scratch_on_bus_list(i)) {
			all_listed = false;
		}
		for (int j = i + 1; j < attached; j++) {
			if (slot[i] == slot[j]) {
				slots_distinct = false;
			}
		}
	}

	for (int i = 0; i < attached; i++) {
		detach_rc[i] = scratch_detach(i);
	}

	zassert_equal(attached, TEST_ATTACH_SCRATCH_DESCS, "attached %d of %d (last rc=%d)",
		      attached, TEST_ATTACH_SCRATCH_DESCS, rc);
	zassert_true(all_listed, "not every descriptor was on the attached list");
	zassert_true(slots_distinct, "two descriptors were given the same DAT slot");

	for (int i = 0; i < TEST_ATTACH_SCRATCH_DESCS; i++) {
		zassert_not_null(slot[i], "descriptor %d attached without a DAT slot", i);
		zassert_ok(detach_rc[i], "detach %d returned %d", i, detach_rc[i]);
		zassert_is_null(scratch_desc[i].controller_priv,
				"descriptor %d kept its DAT slot after detach", i);
		zassert_false(scratch_on_bus_list(i), "descriptor %d still listed after detach", i);
	}
}

ZTEST(dual_board_loopback, test_detach_not_attached)
{
	struct i3c_device_desc desc = {
		.bus = i3c_dev,
		.dev = &i3c_peer_dev,
		.pid = SCRATCH_PID(SCRATCH_PART_NOT_ATTACHED),
	};
	int rc;

	/* Detach rejects a non-member before retaining the pointer, so this
	 * descriptor may safely live on the stack.
	 */
	rc = i3c_detach_i3c_device(&desc);
	zassert_equal(rc, -EALREADY, "expected -EALREADY, got %d", rc);
}

ZTEST(dual_board_loopback, test_attach_duplicate_addr)
{
	int rc;

	I3C_DUAL_BOARD_LOOPBACK_REQUIRE_TARGET_DA();

	rc = scratch_attach_at(0, SCRATCH_PID(SCRATCH_PART_DUPLICATE_ADDR),
			       target_b_desc.dynamic_addr);
	zassert_equal(rc, -EADDRNOTAVAIL, "expected -EADDRNOTAVAIL for duplicate 0x%02x, got %d",
		      target_b_desc.dynamic_addr, rc);

	rc = scratch_detach(0);
	zassert_ok(rc, "detach returned %d", rc);
}
```

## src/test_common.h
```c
/*
 * SPDX-FileCopyrightText: Copyright (c) 2026 Infineon Technologies AG,
 * SPDX-FileCopyrightText: or an affiliate of Infineon Technologies AG. All rights reserved.
 *
 * SPDX-License-Identifier: Apache-2.0
 *
 * Shared declarations for the dual_board_loopback controller test suite:
 * DT-resolved device pointers, Board B's target descriptor, and
 * sync-UART helpers (re-exported via sync_proto.h).
 */

#ifndef I3C_DUAL_BOARD_LOOPBACK_TEST_COMMON_H_
#define I3C_DUAL_BOARD_LOOPBACK_TEST_COMMON_H_

#include <stdint.h>
#include <stddef.h>
#include <stdio.h>
#include <string.h>

#include <zephyr/device.h>
#include <zephyr/drivers/i3c.h>
#include <zephyr/kernel.h>
#include <zephyr/sys/util.h>
#include <zephyr/ztest.h>

#include "sync_proto.h"

#ifdef __cplusplus
extern "C" {
#endif

/* DT handles (defined in main.c). */
extern const struct device *const i3c_dev;
extern const struct device *const sync_uart;

/*
 * Peers on the bus are other boards, or devices a test deliberately made up,
 * so none of them has a local driver instance to point at.  The I3C subsystem
 * dereferences i3c_device_desc.dev without checking it, so every hand-built
 * descriptor in this suite points here rather than holding NULL.
 * i3c_device_desc_alloc() stands in the same kind of placeholder for the
 * devices it discovers at runtime.  Defined in main.c.
 */
extern const struct device i3c_peer_dev;

/* Board B's I3C target descriptor (defined in main.c). */
extern struct i3c_device_desc target_b_desc;

/* Fail the current ZTEST if Board B has no dynamic address. */
#define I3C_DUAL_BOARD_LOOPBACK_REQUIRE_TARGET_DA()                                                \
	zassert_not_equal(target_b_desc.dynamic_addr, 0U,                                          \
			  "test cannot run: target_b has no dynamic address")

/* SETDASA/SETNEWDA/SETGRPA carry the address left-shifted by one (ccc.h). */
#define CCC_ADDR_PAYLOAD(addr) ((uint8_t)((addr) << 1))

/* Target-side DEVICE_ADDR (I3C base + 0x04), as reported by the target's
 * DUMP sync command.
 */
#define TGT_DEVICE_ADDR_DA_VALID BIT(31)
#define TGT_DEVICE_ADDR_DA_MASK  GENMASK(22, 16)

/* Read one 32-bit field out of Board B's register DUMP over the sync UART.
 * The controller's own descriptor cannot answer whether a CCC landed on the
 * target: the driver maintains it from its own bookkeeping regardless of
 * what the target did.  "key" is a DUMP field name including the '='.
 */
static inline int target_dump_field_read(const char *key, uint32_t *value)
{
	char line[SYNC_LINE_MAX];
	const char *p;
	int rc;

	sync_drain(sync_uart);
	sync_send(sync_uart, "DUMP");

	rc = sync_expect_line(sync_uart, "DUMP", line, sizeof(line), K_MSEC(500));
	if (rc != 0) {
		return rc;
	}

	p = strstr(line, key);
	if (p == NULL) {
		return -EPROTO;
	}
	if (sscanf(p + strlen(key), "%8x", value) != 1) {
		return -EPROTO;
	}

	return 0;
}

static inline int target_device_addr_read(uint32_t *device_addr)
{
	return target_dump_field_read("ADDR=", device_addr);
}

/* Re-attach and re-address Board B. Returns 0 when the target is usable
 * again. Safe to call whether or not the descriptor is still attached.
 */
int dual_board_loopback_heal_target(void);

/* Detach any scratch descriptors test_attach.c still has on the bus. */
void dual_board_loopback_attach_cleanup(void);

/*
 * Stage @p len bytes (<= 64) of @p pattern on the target's SLV_TX
 * FIFO via the sync UART.  Required before any private I3C read: reading
 * fewer bytes than the target staged leaves residue that breaks the next
 * transfer, usually with -ENXIO but sometimes as a stale read reporting
 * success.  Returns @p len, and zasserts if the target queued anything
 * else or on protocol error.
 */
static inline size_t dual_board_loopback_stage_read(const uint8_t *pattern, size_t len)
{
	char hex[2U * 64U + 1U];
	char *p = hex;

	zassert_true(len <= 64U, "stage_read len=%zu exceeds 64", len);
	for (size_t i = 0; i < len; i++) {
		p += snprintf(p, 3U, "%02x", pattern[i]);
	}
	*p = '\0';

	sync_send(sync_uart, "STAGE_READ %s", hex);

	char line[SYNC_LINE_MAX];
	int rc = sync_recv_line(sync_uart, line, sizeof(line), K_SECONDS(2));

	zassert_true(rc > 0, "STAGE_READ no reply (%d)", rc);

	int got_len = -1;
	int got_rc = -1;
	int n = sscanf(line, "ACK stage_read %d %d", &got_len, &got_rc);

	zassert_equal(n, 2, "STAGE_READ unexpected reply: '%s'", line);
	zassert_equal(got_len, (int)len, "STAGE_READ len mismatch: asked %zu got %d", len, got_len);
	zassert_equal(got_rc, (int)len, "target i3c_target_tx_write queued %d of %zu bytes", got_rc,
		      len);

	return (size_t)got_rc;
}

#ifdef __cplusplus
}
#endif

#endif /* I3C_DUAL_BOARD_LOOPBACK_TEST_COMMON_H_ */
```

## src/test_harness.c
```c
/*
 * SPDX-FileCopyrightText: Copyright (c) 2026 Infineon Technologies AG,
 * SPDX-FileCopyrightText: or an affiliate of Infineon Technologies AG. All rights reserved.
 *
 * SPDX-License-Identifier: Apache-2.0
 *
 * Meta tests: these exercise the loopback fixture itself (main.c) rather
 * than the I3C driver. They guard the recovery paths the rest of the suite
 * depends on, so a single bus fault cannot cascade into every later test.
 *
 * These issues presented as instability - e.g. 1 in every 25 runs would
 * spontaneously fail horribly.  These tests safeguard the suite itself -
 * if the harness is updated and these fail, the instability may have been
 * reintroduced.
 */

#include "test_common.h"

#include <zephyr/drivers/i3c/ccc.h>

#include "test_identity.h"

/*
 * A NACKed SETDASA makes i3c_bus_setdasa() detach the descriptor, which
 * clears the controller's DAT entry. Re-assigning dynamic_addr alone does
 * not undo that, so every later transfer returns -EINVAL and one NACK
 * cascades into the whole suite failing.
 */
ZTEST(dual_board_loopback, meta_heal_recovers_detached_descriptor)
{
	uint8_t probe = 0x00U;
	struct i3c_msg msg = {
		.buf = &probe,
		.len = 1,
		.flags = I3C_MSG_WRITE | I3C_MSG_STOP,
	};
	int rc;

	I3C_DUAL_BOARD_LOOPBACK_REQUIRE_TARGET_DA();

	/* Reproduce exactly what a failed SETDASA leaves behind. */
	rc = i3c_detach_i3c_device(&target_b_desc);
	zassert_ok(rc, "failed to detach target_b for the test (%d)", rc);

	/* Faking the address back is not enough: the DAT entry is gone. */
	target_b_desc.dynamic_addr = TARGET_STATIC_ADDR;
	zassert_not_equal(i3c_transfer(&target_b_desc, &msg, 1), 0,
			  "transfer unexpectedly succeeded on a detached descriptor");

	rc = dual_board_loopback_heal_target();
	zassert_ok(rc, "heal failed to recover a detached descriptor (%d)", rc);
	zassert_not_equal(target_b_desc.dynamic_addr, 0U, "heal left target_b without a DA");

	rc = i3c_transfer(&target_b_desc, &msg, 1);
	zassert_ok(rc, "target unusable after heal (%d)", rc);
}

/*
 * i3c_ccc_do_setdasa() rejects a descriptor that still holds a dynamic
 * address, so a heal that skips clearing it silently returns -EINVAL and
 * recovers nothing. Guard that ordering.
 */
ZTEST(dual_board_loopback, meta_heal_recovers_stale_dynamic_address)
{
	uint8_t probe = 0x00U;
	struct i3c_msg msg = {
		.buf = &probe,
		.len = 1,
		.flags = I3C_MSG_WRITE | I3C_MSG_STOP,
	};
	int rc;

	I3C_DUAL_BOARD_LOOPBACK_REQUIRE_TARGET_DA();

	/* Attached, but pointing at an address the target no longer answers. */
	target_b_desc.dynamic_addr = TARGET_STATIC_ADDR + 1U;

	rc = dual_board_loopback_heal_target();
	zassert_ok(rc, "heal failed against a stale dynamic address (%d)", rc);
	zassert_equal(target_b_desc.dynamic_addr, TARGET_STATIC_ADDR,
		      "heal left target_b at 0x%02x, expected 0x%02x", target_b_desc.dynamic_addr,
		      TARGET_STATIC_ADDR);

	rc = i3c_transfer(&target_b_desc, &msg, 1);
	zassert_ok(rc, "target unusable after heal (%d)", rc);
}
```

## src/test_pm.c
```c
/*
 * SPDX-FileCopyrightText: Copyright (c) 2026 Infineon Technologies AG,
 * SPDX-FileCopyrightText: or an affiliate of Infineon Technologies AG. All rights reserved.
 *
 * SPDX-License-Identifier: Apache-2.0
 *
 * Power-management: exercises the I3C controller's PM suspend/resume
 * path.  On platforms with a vendor pm_resume hook this is the only
 * test that re-runs the wrapper-gate / peri-clock setup after deep
 * sleep.
 */

#include "test_common.h"

#if defined(CONFIG_PM_DEVICE)

#include <zephyr/pm/device.h>

/*
 * Verifies SUSPEND + RESUME succeed and a post-resume I3C transfer to
 * Board B completes — proves bus, clocks, and attached-device state
 * were fully restored.
 */
ZTEST(dual_board_loopback, test_pm_suspend_resume)
{
	I3C_DUAL_BOARD_LOOPBACK_REQUIRE_TARGET_DA();

	uint8_t tx = 0xA5;
	struct i3c_msg msg = {
		.buf = &tx,
		.len = 1,
		.flags = I3C_MSG_WRITE | I3C_MSG_STOP,
	};
	int rc;

	rc = pm_device_action_run(i3c_dev, PM_DEVICE_ACTION_SUSPEND);
	zassert_ok(rc, "PM suspend failed (%d)", rc);

	rc = pm_device_action_run(i3c_dev, PM_DEVICE_ACTION_RESUME);
	zassert_ok(rc, "PM resume failed (%d)", rc);

	/* Brief settle for clocks/wrapper gate after resume */
	k_msleep(5);

	rc = i3c_transfer(&target_b_desc, &msg, 1);
	zassert_ok(rc, "post-resume transfer failed (%d)", rc);
}

#endif /* CONFIG_PM_DEVICE */
```
